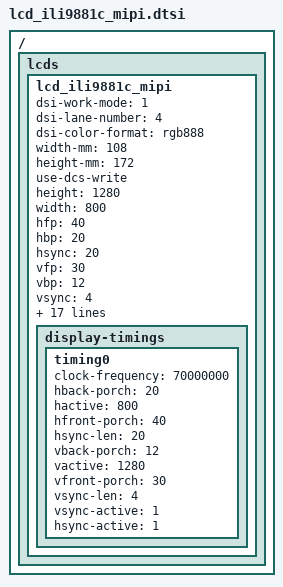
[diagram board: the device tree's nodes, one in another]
// SPDX-License-Identifier: GPL-2.0

/ { lcds: lcds {
	lcd_ili9881c_mipi: lcd_ili9881c_mipi {
		dsi-work-mode = <1>; /* video burst mode*/
		dsi-lane-number = <4>;
		dsi-color-format = "rgb888";
		width-mm = <108>;
		height-mm = <172>;
		use-dcs-write;

		/*mipi info*/
		height = <1280>;
		width = <800>;
		hfp = <40>;
		hbp = <20>;
		hsync = <20>;
		vfp = <30>;
		vbp = <12>;
		vsync = <4>;
		fps = <30>;
		work-mode = <0>;
		rgb-mode = <3>;
		lane-number = <4>;
		phy-bit-clock = <500000000>;
		//phy-esc-clock = <76800000>;
		split-enable = <0>;
		eotp-enable = <0>;
		burst-mode = <0>;
		esd-check-enable = <0>;

		/* DSI_CMD, DSI_MODE, timeout, len, cmd */
		initial-command = [
			39 01 10 04 FF 98 81 03
			39 01 10 02 01 00
			39 01 10 02 02 00
			39 01 10 02 03 53
			39 01 10 02 04 D3
			39 01 10 02 05 00
			39 01 10 02 06 0D
			39 01 10 02 07 08
			39 01 10 02 08 00
			39 01 10 02 09 00
			39 01 10 02 0a 00
			39 01 10 02 0b 00
			39 01 10 02 0c 00
			39 01 10 02 0d 00
			39 01 10 02 0e 00
			39 01 10 02 0f 28
			39 01 10 02 10 28
			39 01 10 02 11 00
			39 01 10 02 12 00
			39 01 10 02 13 00
			39 01 10 02 14 00
			39 01 10 02 15 00
			39 01 10 02 16 00
			39 01 10 02 17 00
			39 01 10 02 18 00
			39 01 10 02 19 00
			39 01 10 02 1a 00
			39 01 10 02 1b 00
			39 01 10 02 1c 00
			39 01 10 02 1d 00
			39 01 10 02 1e 40
			39 01 10 02 1f 80
			39 01 10 02 20 06
			39 01 10 02 21 01
			39 01 10 02 22 00
			39 01 10 02 23 00
			39 01 10 02 24 00
			39 01 10 02 25 00
			39 01 10 02 26 00
			39 01 10 02 27 00
			39 01 10 02 28 33
			39 01 10 02 29 33
			39 01 10 02 2a 00
			39 01 10 02 2b 00
			39 01 10 02 2c 00
			39 01 10 02 2d 00
			39 01 10 02 2e 00
			39 01 10 02 2f 00
			39 01 10 02 30 00
			39 01 10 02 31 00
			39 01 10 02 32 00
			39 01 10 02 33 00
			39 01 10 02 34 03
			39 01 10 02 35 00
			39 01 10 02 36 00
			39 01 10 02 37 00
			39 01 10 02 38 96
			39 01 10 02 39 00
			39 01 10 02 3a 00
			39 01 10 02 3b 00
			39 01 10 02 3c 00
			39 01 10 02 3d 00
			39 01 10 02 3e 00
			39 01 10 02 3f 00
			39 01 10 02 40 00
			39 01 10 02 41 00
			39 01 10 02 42 00
			39 01 10 02 43 00
			39 01 10 02 44 00
			39 01 10 02 50 00
			39 01 10 02 51 23
			39 01 10 02 52 45
			39 01 10 02 53 67
			39 01 10 02 54 89
			39 01 10 02 55 AB
			39 01 10 02 56 01
			39 01 10 02 57 23
			39 01 10 02 58 45
			39 01 10 02 59 67
			39 01 10 02 5a 89
			39 01 10 02 5b AB
			39 01 10 02 5c CD
			39 01 10 02 5d EF
			39 01 10 02 5e 00
			39 01 10 02 5f 08
			39 01 10 02 60 08
			39 01 10 02 61 06
			39 01 10 02 62 06
			39 01 10 02 63 01
			39 01 10 02 64 01
			39 01 10 02 65 00
			39 01 10 02 66 00
			39 01 10 02 67 02
			39 01 10 02 68 15
			39 01 10 02 69 15
			39 01 10 02 6a 14
			39 01 10 02 6b 14
			39 01 10 02 6c 0D
			39 01 10 02 6d 0D
			39 01 10 02 6e 0C
			39 01 10 02 6f 0C
			39 01 10 02 70 0F
			39 01 10 02 71 0F
			39 01 10 02 72 0E
			39 01 10 02 73 0E
			39 01 10 02 74 02
			39 01 10 02 75 08
			39 01 10 02 76 08
			39 01 10 02 77 06
			39 01 10 02 78 06
			39 01 10 02 79 01
			39 01 10 02 7a 01
			39 01 10 02 7b 00
			39 01 10 02 7c 00
			39 01 10 02 7d 02
			39 01 10 02 7e 15
			39 01 10 02 7f 15
			39 01 10 02 80 14
			39 01 10 02 81 14
			39 01 10 02 82 0D
			39 01 10 02 83 0D
			39 01 10 02 84 0C
			39 01 10 02 85 0C
			39 01 10 02 86 0F
			39 01 10 02 87 0F
			39 01 10 02 88 0E
			39 01 10 02 89 0E
			39 01 10 02 8A 02
			39 01 10 04 FF 98 81 04
			39 01 10 02 6E 2B
			39 01 10 02 6F 37
			39 01 10 02 3A A4
			39 01 10 02 8D 1A
			39 01 10 02 87 BA
			39 01 10 02 B2 D1
			39 01 10 02 88 0B
			39 01 10 02 38 01
			39 01 10 02 39 00
			39 01 10 02 B5 07
			39 01 10 02 31 75
			39 01 10 02 3B 98
			//39 01 10 02 2F 01
			39 01 10 04 FF 98 81 01
			39 01 10 02 43 33
			39 01 10 02 22 0A
			39 01 10 02 31 00
			39 01 10 02 53 48
			39 01 10 02 55 48
			39 01 10 02 50 99
			39 01 10 02 51 94
			39 01 10 02 60 10
			39 01 10 02 62 20
			39 01 10 02 A0 00
			39 01 10 02 A1 00
			39 01 10 02 A2 15
			39 01 10 02 A3 14
			39 01 10 02 A4 1B
			39 01 10 02 A5 2F
			39 01 10 02 A6 25
			39 01 10 02 A7 24
			39 01 10 02 A8 80
			39 01 10 02 A9 1F
			39 01 10 02 AA 2C
			39 01 10 02 AB 6C
			39 01 10 02 AC 16
			39 01 10 02 AD 14
			39 01 10 02 AE 4D
			39 01 10 02 AF 20
			39 01 10 02 B0 29
			39 01 10 02 B1 4F
			39 01 10 02 B2 5F
			39 01 10 02 B3 23
			39 01 10 02 C0 00
			39 01 10 02 C1 2E
			39 01 10 02 C2 3B
			39 01 10 02 C3 15
			39 01 10 02 C4 16
			39 01 10 02 C5 28
			39 01 10 02 C6 1A
			39 01 10 02 C7 1C
			39 01 10 02 C8 A7
			39 01 10 02 C9 1B
			39 01 10 02 CA 28
			39 01 10 02 CB 92
			39 01 10 02 CC 1F
			39 01 10 02 CD 1C
			39 01 10 02 CE 4B
			39 01 10 02 CF 1F
			39 01 10 02 D0 28
			39 01 10 02 D1 4E
			39 01 10 02 D2 5C
			39 01 10 02 D3 23
			39 01 10 04 FF 98 81 00
			39 01 10 02 11 00
			39 01 78 02 29 00
			39 01 10 02 35 00
		];
		sleep-in-command = [
			39 01 78 01 28
			39 01 78 01 10
		];
		sleep-out-command = [
			39 01 96 01 11
			39 01 32 01 29
		];
		read-id-command = [
			37 01 00 01 05
			14 01 00 05 fb fc fd fe ff
		];

		display-timings {
			timing0 {
				clock-frequency = <70000000>;
				hback-porch = <20>;
				hactive = <800>;
				hfront-porch = <40>;
				hsync-len = <20>;
				vback-porch = <12>;
				vactive = <1280>;
				vfront-porch = <30>;
				vsync-len = <4>;
				vsync-active = <1>;
				hsync-active = <1>;
			};
		};
	};
};};
